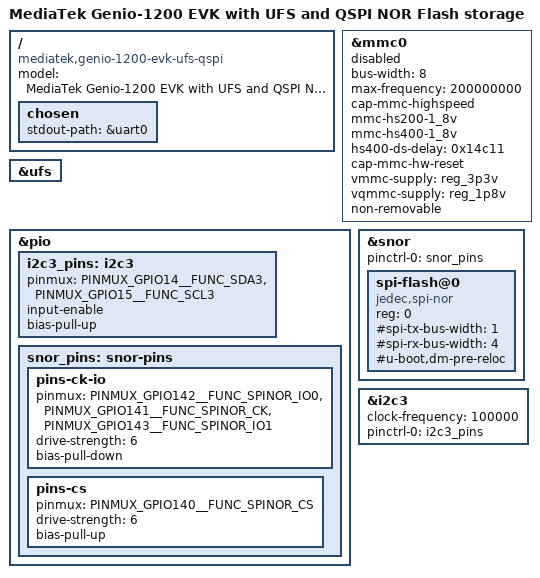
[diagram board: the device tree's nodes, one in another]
// SPDX-License-Identifier: GPL-2.0 OR MIT
/*
 * Copyright (C) 2024 MediaTek INC.
 * Author: Macpaul Lin <macpaul.lin@mediatek.com>
 */

/dts-v1/;

#include "genio-1200-evk-common.dtsi"

/ {
	model = "MediaTek Genio-1200 EVK with UFS and QSPI NOR Flash storage";
	compatible = "mediatek,genio-1200-evk-ufs-qspi", "mediatek,mt8195";

	chosen {
		stdout-path = &uart0;
	};
};

&mmc0 {
	bus-width = <8>;
	max-frequency = <200000000>;
	cap-mmc-highspeed;
	mmc-hs200-1_8v;
	mmc-hs400-1_8v;
	hs400-ds-delay = <0x14c11>;
	cap-mmc-hw-reset;
	vmmc-supply = <&reg_3p3v>;
	vqmmc-supply = <&reg_1p8v>;
	non-removable;
	status = "disabled";
};

&ufs {
	status = "okay";
};

&pio {
	i2c3_pins: i2c3 {
		pinmux = <PINMUX_GPIO14__FUNC_SDA3>,
			 <PINMUX_GPIO15__FUNC_SCL3>;
		input-enable;
		bias-pull-up;
	};

	snor_pins: snor-pins {
		pins-ck-io {
			pinmux = <PINMUX_GPIO142__FUNC_SPINOR_IO0>,
				 <PINMUX_GPIO141__FUNC_SPINOR_CK>,
				 <PINMUX_GPIO143__FUNC_SPINOR_IO1>;
			drive-strength = <6>;
			bias-pull-down;
		};

		pins-cs {
			pinmux = <PINMUX_GPIO140__FUNC_SPINOR_CS>;
			drive-strength = <6>;
			bias-pull-up;
		};
	};
};

&snor {
	pinctrl-names = "default";
	pinctrl-0 = <&snor_pins>;
	status = "okay";

	spi-flash@0 {
		compatible = "jedec,spi-nor";
		reg = <0>;
		#spi-tx-bus-width = <1>;
		#spi-rx-bus-width = <4>;
		#u-boot,dm-pre-reloc;
	};
};

&i2c3 {
	clock-frequency = <100000>;
	pinctrl-0 = <&i2c3_pins>;
	pinctrl-names = "default";
	status = "okay";
};
